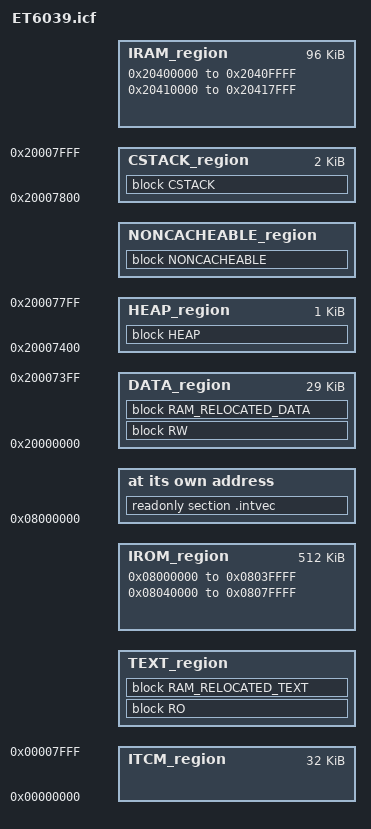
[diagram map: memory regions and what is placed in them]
/*###ICF### Section handled by ICF editor, don't touch! ****/
/*-Editor annotation file-*/
/* IcfEditorFile="$TOOLKIT_DIR$\config\ide\IcfEditor\cortex_v1_4.xml" */
/*-Specials-*/
define symbol __ICFEDIT_intvec_start__ = 0x08000000;
/*-Memory Regions-*/
define symbol __ICFEDIT_region_IROM1_start__ = 0x08000000;
define symbol __ICFEDIT_region_IROM1_end__   = 0x0803FFFF;
define symbol __ICFEDIT_region_IROM2_start__ = 0x08040000;
define symbol __ICFEDIT_region_IROM2_end__   = 0x0807FFFF;
define symbol __ICFEDIT_region_EROM1_start__ = 0x0;
define symbol __ICFEDIT_region_EROM1_end__   = 0x0;
define symbol __ICFEDIT_region_EROM2_start__ = 0x0;
define symbol __ICFEDIT_region_EROM2_end__   = 0x0;
define symbol __ICFEDIT_region_EROM3_start__ = 0x0;
define symbol __ICFEDIT_region_EROM3_end__   = 0x0;
define symbol __ICFEDIT_region_IRAM1_start__ = 0x20400000;
define symbol __ICFEDIT_region_IRAM1_end__   = 0x2040FFFF;
define symbol __ICFEDIT_region_IRAM2_start__ = 0x20410000;
define symbol __ICFEDIT_region_IRAM2_end__   = 0x20417FFF;
define symbol __ICFEDIT_region_ERAM1_start__ = 0x0;
define symbol __ICFEDIT_region_ERAM1_end__   = 0x0;
define symbol __ICFEDIT_region_ERAM2_start__ = 0x0;
define symbol __ICFEDIT_region_ERAM2_end__   = 0x0;
define symbol __ICFEDIT_region_ERAM3_start__ = 0x0;
define symbol __ICFEDIT_region_ERAM3_end__   = 0x0;
/*-Sizes-*/
define symbol __ICFEDIT_size_cstack__     = 0x800;
define symbol __ICFEDIT_size_proc_stack__ = 0x0;
define symbol __ICFEDIT_size_heap__       = 0x400;
/**** End of ICF editor section. ###ICF###*/

define symbol __ITCM_BASE         = 0x00000000;
define symbol __ITCM_END          = 0x00007FFF;

define symbol __DTCM_BASE         = 0x20000000;
define symbol __DTCM_END          = 0x20007FFF;



/*----------------------------------------------------------------------------
  User Stack & Heap boundary definition
 *----------------------------------------------------------------------------*/
define symbol __STACK_BASE    = __DTCM_END - __ICFEDIT_size_cstack__ + 1;
define symbol __STACK_END     = __DTCM_END;

define symbol __DATA_BASE     = __DTCM_BASE;
define symbol __DATA_END      = __DTCM_END - __ICFEDIT_size_cstack__ - __ICFEDIT_size_heap__;

define symbol __HEAP_BASE     = __DATA_END + 1;
define symbol __HEAP_END      = __DATA_END + __ICFEDIT_size_heap__;


define memory mem with size = 4G;
define region IROM_region     =   mem:[from __ICFEDIT_region_IROM1_start__ to __ICFEDIT_region_IROM1_end__]
                                | mem:[from __ICFEDIT_region_IROM2_start__ to __ICFEDIT_region_IROM2_end__];
define region EROM_region     =   mem:[from __ICFEDIT_region_EROM1_start__ to __ICFEDIT_region_EROM1_end__]
                                | mem:[from __ICFEDIT_region_EROM2_start__ to __ICFEDIT_region_EROM2_end__]
                                | mem:[from __ICFEDIT_region_EROM3_start__ to __ICFEDIT_region_EROM3_end__];
define region IRAM_region     =   mem:[from __ICFEDIT_region_IRAM1_start__ to __ICFEDIT_region_IRAM1_end__]
                                | mem:[from __ICFEDIT_region_IRAM2_start__ to __ICFEDIT_region_IRAM2_end__];
define region ERAM_region     =   mem:[from __ICFEDIT_region_ERAM1_start__ to __ICFEDIT_region_ERAM1_end__]
                                | mem:[from __ICFEDIT_region_ERAM2_start__ to __ICFEDIT_region_ERAM2_end__]
                                | mem:[from __ICFEDIT_region_ERAM3_start__ to __ICFEDIT_region_ERAM3_end__];
define region ITCM_region     =   mem:[from __ITCM_BASE to __ITCM_END];   

/*----------------------------------------------------------------------------
  Select the position of the code segment.
 *----------------------------------------------------------------------------*/
if(__ICFEDIT_intvec_start__ == __ICFEDIT_region_IROM1_start__)
{
    define region TEXT_region           = IROM_region;
}
else if(__ICFEDIT_intvec_start__ == __ICFEDIT_region_IRAM1_start__)
{
    define region TEXT_region           = IRAM_region;
}
else if(__ICFEDIT_intvec_start__ == __ITCM_BASE)
{
    define region TEXT_region           = ITCM_region;
} 
else
{
#error Incorrect download address(FLASH->0x08000000,ITCM->0x00,RAM->0x20400000)
}

define region DATA_region     			= mem:[from __DATA_BASE to __DATA_END];
define region CSTACK_region   			= mem:[from __STACK_BASE to __STACK_END];
define region HEAP_region     			= mem:[from __HEAP_BASE to __HEAP_END];
define region NONCACHEABLE_region    	= IRAM_region;

/*----------------------------------------------------------------------------
  Block definition
 *----------------------------------------------------------------------------*/
define block RO                    { readonly };
define block RW                    { readwrite };
define block CSTACK                with alignment = 8, size = __ICFEDIT_size_cstack__ { };
define block HEAP                  with alignment = 8, size = __ICFEDIT_size_heap__ { };
define block NONCACHEABLE          { section .NonCacheable.data, section .NonCacheable.bss};
define block RAM_RELOCATED_TEXT    with alignment = 4, end alignment = 4 { section .textrw, section .RamRelocated.text };
define block RAM_RELOCATED_DATA    { section .RamRelocated.data, section .RamRelocated.bss };

initialize by copy { readwrite };

place at address mem:__ICFEDIT_intvec_start__ { readonly section .intvec };

place in TEXT_region  				{ block RO };
place in DATA_region  				{ block RW };
place in CSTACK_region  			{ block CSTACK };
place in HEAP_region  				{ block HEAP };
place in NONCACHEABLE_region  		{ block NONCACHEABLE };
place in TEXT_region  				{ block RAM_RELOCATED_TEXT };
place in DATA_region  				{ block RAM_RELOCATED_DATA };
